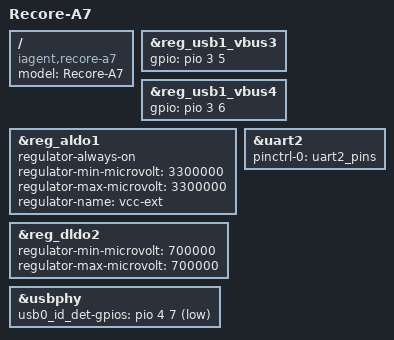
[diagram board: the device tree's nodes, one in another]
// SPDX-License-Identifier: (GPL-2.0+ OR MIT)

/dts-v1/;

#include "sun50i-a64-recore.dtsi"
#include <dt-bindings/usb/pd.h>

/ {
	model = "Recore-A7";
	compatible = "iagent,recore-a7", "allwinner,sun50i-a64";
};

&reg_usb1_vbus3 {
	gpio = <&pio 3 5 GPIO_ACTIVE_HIGH> ; /* PD5 */
};

&reg_usb1_vbus4 {
	gpio = <&pio 3 6 GPIO_ACTIVE_HIGH> ; /* PD6 */
};

&reg_aldo1 {
	regulator-always-on;
	regulator-min-microvolt = <3300000>;
	regulator-max-microvolt = <3300000>;
	regulator-name = "vcc-ext";
};

/* Set over current to lowest value: 35 A = 700 mV */
&reg_dldo2 {
	regulator-min-microvolt = <700000>;
	regulator-max-microvolt = <700000>;
};

&usbphy {
	usb0_id_det-gpios   = <&pio 4 7 GPIO_ACTIVE_LOW>;
};
&uart2 {
	pinctrl-names = "default";
	pinctrl-0 = <&uart2_pins>;
	status = "okay";
};
